# PIC32CM6408PL10048 register map
Vendor: Microchip Technology; Series: PIC32CMPL10; File version: 0
Microchip PIC32CM6408PL10048 Microcontroller
CPU: CM0+ r0p0, little endian, no MPU, no FPU, VTOR, 2 interrupt priority bits, 15 interrupts
Registers are 32-bit, read-write, reset 0x0 unless marked. A register's access mark holds for its fields unless they carry their own. Offsets are from the block's base; lines under a group give offsets from that group; [hi:lo] are bit positions; {n}, {i} and the like mark numbered series; 'fields as' and 'values as' point back to an identical list; <NAME> marks a mode.

## Memory map
0x40000000 PAC size 0x40 — Peripheral Access Controller
0x40000400 PM size 0x10 — Power Manager
0x40000800 MCLK size 0x20 — Main Clock
0x40000C00 RSTC size 0x10 — Reset Controller
0x40001000 OSCCTRL size 0x30 — Oscillators Controller
0x40001400 OSC32KCTRL size 0x30 — 32.768 kHz Oscillators Controller
0x40001800 SUPC size 0x30 — Supply Controller
0x40001C00 GCLK size 0xB4 — Generic Clock Controller
0x40002000 WDT size 0xD — Watchdog Timer
0x40002400 RTC size 0x25 — Real-Time Counter
0x40002800 EIC size 0x24 — External Interrupt Controller
0x41000000 PORT size 0x100 — I/O Pin Controller
0x41002000 DSU size 0x2000 — Device Service Unit
0x41004000 NVMCTRL size 0x30 — Non-Volatile Memory Controller
0x41006000 DMAC size 0x50 — Direct Memory Access Controller
0x41008000 MTB size 0x1000 — Cortex-M0+ Micro-Trace Buffer
0x4100A000 HMATRIXHS size 0x150 — HSB Matrix
0x42000000 EVSYS size 0xDC — Event System
0x42000400 SERCOM0 size 0x31 — Serial Communication Interface
0x42000800 SERCOM1 size 0x31
0x42000C00 TC0 size 0x38 — Timer/Counter
0x42001000 TC1 size 0x38
0x42001400 TC2 size 0x38
0x42001800 TCC0 size 0x80 — Timer/Counter for Control Applications
0x42001C00 ADC0 size 0x80 — Analog-to-Digital Converter
0x42002000 AC size 0x84 — Analog Comparator
0x42002400 CCL size 0x2C — Configurable Custom Logic
0x42002C00 SYSCTRL size 0x8C — System Controller
0x50000000 PORT_IOBUS size 0x100
0xE000E000 SystemControl size 0xD34 — System Control Registers
0xE000E010 SysTick size 0x10 — System timer
0xE000E100 NVIC size 0x310 — Nested Vectored Interrupt Controller

## Interrupts
0 SYSTEM (MCLK, OSC32KCTRL, OSCCTRL, PAC, SUPC)
1 WDT
2 RTC
3 EIC
4 NVMCTRL
5 DMAC
6 EVSYS
7 SERCOM0
8 SERCOM1
9 TC0
10 TC1
11 TC2
12 TCC0
13 ADC0
14 AC

## AC — Analog Comparator
Base 0x42002000
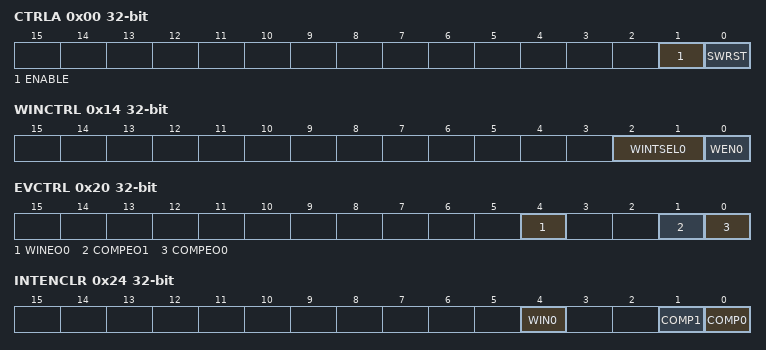
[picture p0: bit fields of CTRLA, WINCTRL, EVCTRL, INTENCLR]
0x00 CTRLA — Control A
  [1] ENABLE — Global Enable
  [0] SWRST — Software Reset
0x04 CTRLB — Control B
  [1:0] INTREF — Internal Reference Selection
    0=1V024 (Internal 1.024V reference); 1=2V048 (Internal 2.048V reference); 2=4V096 (Internal 4.096V reference); 3=2V500 (Internal 2.500V reference)
0x14 WINCTRL — Window Control
  [2:1] WINTSEL0 — Window 0 Interrupt Selection
    0=ABOVE (Interrupt when the signal goes above the window); 1=INSIDE (Interrupt when the signal goes inside the window); 2=BELOW (Interrupt when the signal goes below the window); 3=OUTSIDE (Interrupt when the signal goes outside the window)
  [0] WEN0 — Window 0 Enable
0x20 EVCTRL — Event Control
  [4] WINEO0 — Window 0 Event Output Enable
  [1] COMPEO1 — Comparator 1 Event Output Enable
  [0] COMPEO0 — Comparator 0 Event Output Enable
0x24 INTENCLR write-1-clears — Interrupt Enable Clear
  [4] WIN0 — Window 0 Interrupt Enable
  [1] COMP1 — Comparator 1 Interrupt Enable
  [0] COMP0 — Comparator 0 Interrupt Enable
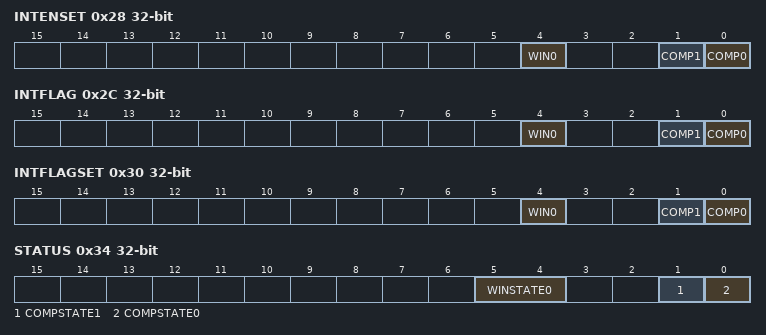
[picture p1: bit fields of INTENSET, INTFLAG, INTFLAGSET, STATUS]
0x28 INTENSET write-1-sets — Interrupt Enable Set
  fields as INTENCLR
0x2C INTFLAG write-1-clears — Interrupt Flag Status and Clear
  [4] WIN0 — Window 0 Interrupt Flag
  [1] COMP1 — Comparator 1 Interrupt Flag
  [0] COMP0 — Comparator 0 Interrupt Flag
0x30 INTFLAGSET write-1-clears — Interrupt Flag Set
  fields as INTFLAG
0x34 STATUS ro
  [5:4] WINSTATE0 — Window 0 State
    0=ABOVE (The input signal is above window n); 1=INSIDE (The input signal is inside window n); 2=BELOW (The input signal is below window n)
  [1] COMPSTATE1 — Comparator 1 State
  [0] COMPSTATE0 — Comparator 0 State
{0x40+0x10*i} COMP[{i}] (i=0..1) group
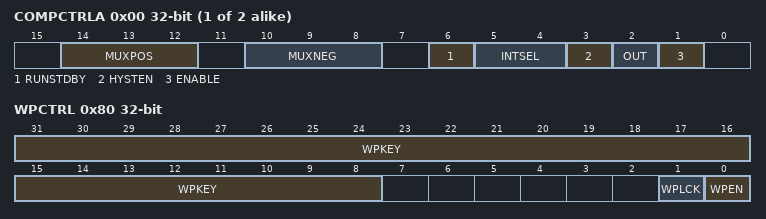
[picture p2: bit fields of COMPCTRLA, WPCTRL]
  0x00 COMPCTRLA — Comparator # Comparator Control A
    [14:12] MUXPOS — Positive Input Selection
      {v}=AINP{v} (Positive pin {v}) (v=0..3); 5=AINP5 (Positive pin 5); 6=AINP6 (Positive pin 6); 7=VDDIO2DIV10
    [10:8] MUXNEG — Negative Input Selection
      0=AINN0 (Negative pin 0); 1=AINN1 (Negative pin 1); 2=AINN2 (Negative pin 2); 7=VREFSCALE (Voltage Reference Scaler)
    [6] RUNSTDBY — Run in Standby
    [5:4] INTSEL — Interrupt Selection
      0=TOGGLE (Interrupt on comparator n output toggle); 1=RISING (Interrupt on comparator n output rising edge); 2=FALLING (Interrupt on comparator n output falling edge)
    [3] HYSTEN — Hysteresis Enable
    [2] OUT — Output Enable
    [1] ENABLE — Comparator Enable
  0x04 COMPCTRLB — Comparator # Comparator Control B
    [1:0] REFSEL — Reference Selection
      0=VDD; 1=INTVREF (Internal reference voltage, as defined by the Internal Reference Selection bit field in the Control B register (CTRLB.INTREF)); 2=EXTVREF (External reference pin)
  0x08 COMPSCALER — Comparator # Comparator Scaler
    [7:0] VALUE — Scaled Reference Voltage
0x80 WPCTRL — Write Protection Control
  [31:8] WPKEY — Write Protection Key
    0x414320=KEY (Allow writes to the WPCTRL register)
  [1] WPLCK — Write Protection Lock
  [0] WPEN — Write Protection Enable

## Licence text in the file
Copyright (c) 2026 Microchip Technology Inc. SPDX-License-Identifier: Apache-2.0 Licensed under the Apache License, Version 2.0 (the "License"); you may not use this file except in compliance with the License. You may obtain a copy of the License at http://www.apache.org/licenses/LICENSE-2.0 Unless required by applicable law or agreed to in writing, software distributed under the License is distributed on an "AS IS" BASIS, WITHOUT WARRANTIES OR CONDITIONS OF ANY KIND, either express or implied. See the License for the specific language governing permissions and limitations under the License.
